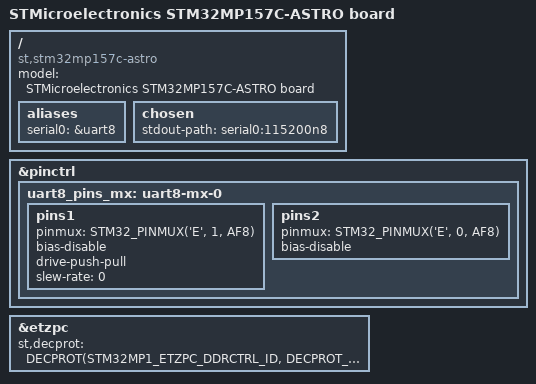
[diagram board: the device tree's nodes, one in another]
// SPDX-License-Identifier: (GPL-2.0+ OR BSD-3-Clause)
/*
 * Copyright (C) STMicroelectronics 2019 - All Rights Reserved
 * Author: Alexandre Torgue <alexandre.torgue@st.com> for STMicroelectronics.
 */
/dts-v1/;

#include "stm32mp157.dtsi"
#include "stm32mp15xc.dtsi"
#include "stm32mp15-pinctrl.dtsi"
#include "stm32mp15xxac-pinctrl.dtsi"
#include "stm32mp157c-astro.dtsi"
#include <dt-bindings/soc/st,stm32-etzpc.h>

/ {
	model = "STMicroelectronics STM32MP157C-ASTRO board";
	compatible = "st,stm32mp157c-astro", "st,stm32mp157";

	aliases {
		serial0 = &uart8;
	};

	chosen {
		stdout-path = "serial0:115200n8";
	};
};

&pinctrl {
	uart8_pins_mx: uart8-mx-0 {
		pins1 {
			pinmux = <STM32_PINMUX('E', 1, AF8)>; /* UART8_TX */
			bias-disable;
			drive-push-pull;
			slew-rate = <0>;
		};
		pins2 {
			pinmux = <STM32_PINMUX('E', 0, AF8)>; /* UART8_RX */
			bias-disable;
		};
	};
};

&etzpc {
	st,decprot = <
	/*"NS_R S_W" peripherals*/
	DECPROT(STM32MP1_ETZPC_DDRCTRL_ID, DECPROT_NS_R_S_W, DECPROT_LOCK)
	DECPROT(STM32MP1_ETZPC_DDRPHYC_ID, DECPROT_NS_R_S_W, DECPROT_LOCK)
	/*"Non Secured" peripherals*/
	DECPROT(STM32MP1_ETZPC_DMA1_ID, DECPROT_NS_RW, DECPROT_UNLOCK)
	DECPROT(STM32MP1_ETZPC_DMAMUX_ID, DECPROT_NS_RW, DECPROT_UNLOCK)
	DECPROT(STM32MP1_ETZPC_ETH_ID, DECPROT_NS_RW, DECPROT_UNLOCK)
	DECPROT(STM32MP1_ETZPC_RNG1_ID, DECPROT_NS_RW, DECPROT_UNLOCK)
	DECPROT(STM32MP1_ETZPC_UART8_ID, DECPROT_NS_RW, DECPROT_UNLOCK)
	DECPROT(STM32MP1_ETZPC_OTG_ID, DECPROT_NS_RW, DECPROT_UNLOCK)
	/*"Secured" peripherals*/
	DECPROT(STM32MP1_ETZPC_STGENC_ID, DECPROT_S_RW, DECPROT_UNLOCK)
	/*"Mcu Isolation" peripherals*/
	DECPROT(STM32MP1_ETZPC_DMA2_ID, DECPROT_MCU_ISOLATION, DECPROT_UNLOCK)
	DECPROT(STM32MP1_ETZPC_TT_FDCAN_ID, DECPROT_MCU_ISOLATION, DECPROT_UNLOCK)
	DECPROT(STM32MP1_ETZPC_SPI1_ID, DECPROT_MCU_ISOLATION, DECPROT_UNLOCK)
	DECPROT(STM32MP1_ETZPC_TIM2_ID, DECPROT_MCU_ISOLATION, DECPROT_UNLOCK)
	DECPROT(STM32MP1_ETZPC_TIM5_ID, DECPROT_MCU_ISOLATION, DECPROT_UNLOCK)
	DECPROT(STM32MP1_ETZPC_USART2_ID, DECPROT_MCU_ISOLATION, DECPROT_UNLOCK)
	DECPROT(STM32MP1_ETZPC_USART3_ID, DECPROT_MCU_ISOLATION, DECPROT_UNLOCK)
	DECPROT(STM32MP1_ETZPC_USART6_ID, DECPROT_MCU_ISOLATION, DECPROT_UNLOCK)
	>;
};
